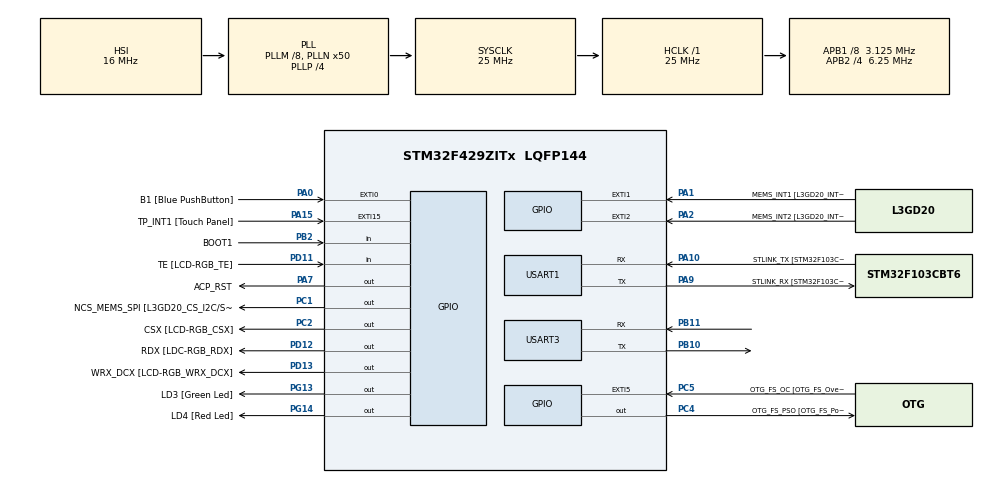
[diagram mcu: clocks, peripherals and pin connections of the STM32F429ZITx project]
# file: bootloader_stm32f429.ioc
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Mcu.Family=STM32F4
Mcu.Name=STM32F429ZITx
Mcu.Package=LQFP144
NVIC.PriorityGroup=NVIC_PRIORITYGROUP_0
PA0/WKUP.GPIO_Label=B1 [Blue PushButton]
PA0/WKUP.GPIO_ModeDefaultEXTI=GPIO_MODE_EVT_RISING
PA0/WKUP.GPIO_PuPd=GPIO_NOPULL
PA0/WKUP.Signal=GPXTI0
PA1.GPIO_Label=MEMS_INT1 [L3GD20_INT1]
PA1.GPIO_ModeDefaultEXTI=GPIO_MODE_EVT_RISING
PA1.GPIO_PuPd=GPIO_NOPULL
PA1.Signal=GPXTI1
PA10.GPIO_Label=STLINK_TX [STM32F103CBT6_PA2]
PA10.Mode=Asynchronous
PA10.Signal=USART1_RX
PA11.GPIO_Label=R4
PA11.GPIO_Mode=GPIO_MODE_AF_PP
PA11.GPIO_PuPd=GPIO_NOPULL
PA11.GPIO_Speed=GPIO_SPEED_FREQ_LOW
PA11.Signal=LTDC_R4
PA12.GPIO_Label=R5
PA12.GPIO_Mode=GPIO_MODE_AF_PP
PA12.GPIO_PuPd=GPIO_NOPULL
PA12.GPIO_Speed=GPIO_SPEED_FREQ_LOW
PA12.Signal=LTDC_R5
PA13.GPIO_Label=SWDIO
PA13.Signal=SYS_JTMS-SWDIO
PA14.GPIO_Label=SWCLK
PA14.Signal=SYS_JTCK-SWCLK
PA15.GPIO_Label=TP_INT1 [Touch Panel]
PA15.GPIO_ModeDefaultEXTI=GPIO_MODE_EVT_RISING
PA15.GPIO_PuPd=GPIO_NOPULL
PA15.Signal=GPXTI15
PA2.GPIO_Label=MEMS_INT2 [L3GD20_INT2]
PA2.GPIO_ModeDefaultEXTI=GPIO_MODE_EVT_RISING
PA2.GPIO_PuPd=GPIO_NOPULL
PA2.Signal=GPXTI2
PA3.GPIO_Label=B5
PA3.GPIO_Mode=GPIO_MODE_AF_PP
PA3.GPIO_PuPd=GPIO_NOPULL
PA3.GPIO_Speed=GPIO_SPEED_FREQ_LOW
PA3.Signal=LTDC_B5
PA4.GPIO_Label=VSYNC
PA4.GPIO_Mode=GPIO_MODE_AF_PP
PA4.GPIO_PuPd=GPIO_NOPULL
PA4.GPIO_Speed=GPIO_SPEED_FREQ_LOW
PA4.Signal=LTDC_VSYNC
PA6.GPIO_Label=G2
PA6.GPIO_Mode=GPIO_MODE_AF_PP
PA6.GPIO_PuPd=GPIO_NOPULL
PA6.GPIO_Speed=GPIO_SPEED_FREQ_LOW
PA6.Signal=LTDC_G2
PA7.GPIO_Label=ACP_RST
PA7.GPIO_Mode=GPIO_MODE_OUTPUT_PP
PA7.GPIO_PuPd=GPIO_NOPULL
PA7.GPIO_Speed=GPIO_SPEED_FREQ_LOW
PA7.Signal=GPIO_Output
PA8.GPIO_Label=I2C3_SCL [ACP/RF_SCL]
PA8.GPIO_Mode=GPIO_MODE_AF_OD
PA8.GPIO_PuPd=GPIO_NOPULL
PA8.GPIO_Speed=GPIO_SPEED_FREQ_LOW
PA8.Signal=I2C3_SCL
PA9.GPIO_Label=STLINK_RX [STM32F103CBT6_PA3]
PA9.Mode=Asynchronous
PA9.Signal=USART1_TX
PB0.GPIO_Label=R3
PB0.GPIO_Mode=GPIO_MODE_AF_PP
PB0.GPIO_PuPd=GPIO_NOPULL
PB0.GPIO_Speed=GPIO_SPEED_FREQ_LOW
PB0.Signal=LTDC_R3
PB1.GPIO_Label=R6
PB1.GPIO_Mode=GPIO_MODE_AF_PP
PB1.GPIO_PuPd=GPIO_NOPULL
PB1.GPIO_Speed=GPIO_SPEED_FREQ_LOW
PB1.Signal=LTDC_R6
PB10.Mode=Asynchronous
PB10.Signal=USART3_TX
PB11.Mode=Asynchronous
PB11.Signal=USART3_RX
PB12.GPIO_Label=OTG_HS_ID
PB12.GPIO_Mode=GPIO_MODE_AF_PP
PB12.GPIO_PuPd=GPIO_NOPULL
PB12.GPIO_Speed=GPIO_SPEED_FREQ_LOW
PB12.Signal=USB_OTG_HS_ID
PB13.GPIO_Label=VBUS_HS
PB13.GPIO_Mode=GPIO_MODE_INPUT
PB13.GPIO_PuPd=GPIO_NOPULL
PB13.Signal=USB_OTG_HS_VBUS
PB14.GPIO_Label=OTG_HS_DM
PB14.GPIO_Mode=GPIO_MODE_AF_PP
PB14.GPIO_PuPd=GPIO_NOPULL
PB14.GPIO_Speed=GPIO_SPEED_FREQ_LOW
PB14.Signal=USB_OTG_HS_DM
PB15.GPIO_Label=OTG_HS_DP
PB15.GPIO_Mode=GPIO_MODE_AF_PP
PB15.GPIO_PuPd=GPIO_NOPULL
PB15.GPIO_Speed=GPIO_SPEED_FREQ_LOW
PB15.Signal=USB_OTG_HS_DP
PB2/BOOT1.GPIO_Label=BOOT1
PB2/BOOT1.GPIO_Mode=GPIO_MODE_INPUT
PB2/BOOT1.GPIO_PuPd=GPIO_NOPULL
PB2/BOOT1.Signal=GPIO_Input
PB5.GPIO_Label=SDCKE1
PB5.GPIO_Mode=GPIO_MODE_AF_PP
PB5.GPIO_PuPd=GPIO_NOPULL
PB5.GPIO_Speed=GPIO_SPEED_FREQ_VERY_HIGH
PB5.Signal=FMC_SDCKE1
PB6.GPIO_Label=SDNE1 [SDRAM_CS]
PB6.GPIO_Mode=GPIO_MODE_AF_PP
PB6.GPIO_PuPd=GPIO_NOPULL
PB6.GPIO_Speed=GPIO_SPEED_FREQ_VERY_HIGH
PB6.Signal=FMC_SDNE1
PB8.GPIO_Label=B6
PB8.GPIO_Mode=GPIO_MODE_AF_PP
PB8.GPIO_PuPd=GPIO_NOPULL
PB8.GPIO_Speed=GPIO_SPEED_FREQ_LOW
PB8.Signal=LTDC_B6
PB9.GPIO_Label=B7
PB9.GPIO_Mode=GPIO_MODE_AF_PP
PB9.GPIO_PuPd=GPIO_NOPULL
PB9.GPIO_Speed=GPIO_SPEED_FREQ_LOW
PB9.Signal=LTDC_B7
PC0.GPIO_Label=SDNWE
PC0.GPIO_Mode=GPIO_MODE_AF_PP
PC0.GPIO_PuPd=GPIO_NOPULL
PC0.GPIO_Speed=GPIO_SPEED_FREQ_VERY_HIGH
PC0.Signal=FMC_SDNWE
PC1.GPIO_Label=NCS_MEMS_SPI [L3GD20_CS_I2C/SPI]
PC1.GPIO_Mode=GPIO_MODE_OUTPUT_PP
PC1.GPIO_PuPd=GPIO_NOPULL
PC1.GPIO_Speed=GPIO_SPEED_FREQ_LOW
PC1.Signal=GPIO_Output
PC14/OSC32_IN.GPIO_Label=PC14-OSC32_IN
PC14/OSC32_IN.Signal=RCC_OSC32_IN
PC15/OSC32_OUT.GPIO_Label=PC15-OSC32_OUT
PC15/OSC32_OUT.Signal=RCC_OSC32_OUT
PC2.GPIO_Label=CSX [LCD-RGB_CSX]
PC2.GPIO_Mode=GPIO_MODE_OUTPUT_PP
PC2.GPIO_PuPd=GPIO_NOPULL
PC2.GPIO_Speed=GPIO_SPEED_FREQ_LOW
PC2.Signal=GPIO_Output
PC4.GPIO_Label=OTG_FS_PSO [OTG_FS_PowerSwitchOn]
PC4.GPIO_Mode=GPIO_MODE_OUTPUT_PP
PC4.GPIO_PuPd=GPIO_NOPULL
PC4.GPIO_Speed=GPIO_SPEED_FREQ_LOW
PC4.Signal=GPIO_Output
PC5.GPIO_Label=OTG_FS_OC [OTG_FS_OverCurrent]
PC5.GPIO_ModeDefaultEXTI=GPIO_MODE_EVT_RISING
PC5.Signal=GPXTI5
PC6.GPIO_Label=HSYNC
PC6.GPIO_Mode=GPIO_MODE_AF_PP
PC6.GPIO_PuPd=GPIO_NOPULL
PC6.GPIO_Speed=GPIO_SPEED_FREQ_LOW
PC6.Signal=LTDC_HSYNC
PC7.GPIO_Label=G6
PC7.GPIO_Mode=GPIO_MODE_AF_PP
PC7.GPIO_PuPd=GPIO_NOPULL
PC7.GPIO_Speed=GPIO_SPEED_FREQ_LOW
PC7.Signal=LTDC_G6
PC9.GPIO_Label=I2C3_SDA [ACP/RF_SDA]
PC9.GPIO_Mode=GPIO_MODE_AF_OD
PC9.GPIO_PuPd=GPIO_NOPULL
PC9.GPIO_Speed=GPIO_SPEED_FREQ_LOW
PC9.Signal=I2C3_SDA
PD0.GPIO_Label=D2
PD0.GPIO_Mode=GPIO_MODE_AF_PP
PD0.GPIO_PuPd=GPIO_NOPULL
PD0.GPIO_Speed=GPIO_SPEED_FREQ_VERY_HIGH
PD0.Signal=FMC_D2_DA2
PD1.GPIO_Label=D3
PD1.GPIO_Mode=GPIO_MODE_AF_PP
PD1.GPIO_PuPd=GPIO_NOPULL
PD1.GPIO_Speed=GPIO_SPEED_FREQ_VERY_HIGH
PD1.Signal=FMC_D3_DA3
PD10.GPIO_Label=D15
PD10.GPIO_Mode=GPIO_MODE_AF_PP
PD10.GPIO_PuPd=GPIO_NOPULL
PD10.GPIO_Speed=GPIO_SPEED_FREQ_VERY_HIGH
PD10.Signal=FMC_D15_DA15
PD11.GPIO_Label=TE [LCD-RGB_TE]
PD11.GPIO_Mode=GPIO_MODE_INPUT
PD11.GPIO_PuPd=GPIO_NOPULL
PD11.Signal=GPIO_Input
PD12.GPIO_Label=RDX [LDC-RGB_RDX]
PD12.GPIO_Mode=GPIO_MODE_OUTPUT_PP
PD12.GPIO_PuPd=GPIO_NOPULL
PD12.GPIO_Speed=GPIO_SPEED_FREQ_LOW
PD12.Signal=GPIO_Output
PD13.GPIO_Label=WRX_DCX [LCD-RGB_WRX_DCX]
PD13.GPIO_Mode=GPIO_MODE_OUTPUT_PP
PD13.GPIO_PuPd=GPIO_NOPULL
PD13.GPIO_Speed=GPIO_SPEED_FREQ_LOW
PD13.Signal=GPIO_Output
PD14.GPIO_Label=D0
PD14.GPIO_Mode=GPIO_MODE_AF_PP
PD14.GPIO_PuPd=GPIO_NOPULL
PD14.GPIO_Speed=GPIO_SPEED_FREQ_VERY_HIGH
PD14.Signal=FMC_D0_DA0
PD15.GPIO_Label=D1
PD15.GPIO_Mode=GPIO_MODE_AF_PP
PD15.GPIO_PuPd=GPIO_NOPULL
PD15.GPIO_Speed=GPIO_SPEED_FREQ_VERY_HIGH
PD15.Signal=FMC_D1_DA1
PD3.GPIO_Label=G7
PD3.GPIO_Mode=GPIO_MODE_AF_PP
PD3.GPIO_PuPd=GPIO_NOPULL
PD3.GPIO_Speed=GPIO_SPEED_FREQ_LOW
PD3.Signal=LTDC_G7
PD6.GPIO_Label=B2
PD6.GPIO_Mode=GPIO_MODE_AF_PP
PD6.GPIO_PuPd=GPIO_NOPULL
PD6.GPIO_Speed=GPIO_SPEED_FREQ_LOW
PD6.Signal=LTDC_B2
PD8.GPIO_Label=D13
PD8.GPIO_Mode=GPIO_MODE_AF_PP
PD8.GPIO_PuPd=GPIO_NOPULL
PD8.GPIO_Speed=GPIO_SPEED_FREQ_VERY_HIGH
PD8.Signal=FMC_D13_DA13
PD9.GPIO_Label=D14
PD9.GPIO_Mode=GPIO_MODE_AF_PP
PD9.GPIO_PuPd=GPIO_NOPULL
PD9.GPIO_Speed=GPIO_SPEED_FREQ_VERY_HIGH
PD9.Signal=FMC_D14_DA14
PE0.GPIO_Label=NBL0 [SDRAM_LDQM]
PE0.GPIO_Mode=GPIO_MODE_AF_PP
PE0.GPIO_PuPd=GPIO_NOPULL
PE0.GPIO_Speed=GPIO_SPEED_FREQ_VERY_HIGH
PE0.Signal=FMC_NBL0
PE1.GPIO_Label=NBL1 [SDRAM_UDQM]
PE1.GPIO_Mode=GPIO_MODE_AF_PP
PE1.GPIO_PuPd=GPIO_NOPULL
PE1.GPIO_Speed=GPIO_SPEED_FREQ_VERY_HIGH
PE1.Signal=FMC_NBL1
PE10.GPIO_Label=D7
PE10.GPIO_Mode=GPIO_MODE_AF_PP
PE10.GPIO_PuPd=GPIO_NOPULL
PE10.GPIO_Speed=GPIO_SPEED_FREQ_VERY_HIGH
PE10.Signal=FMC_D7_DA7
PE11.GPIO_Label=D8
PE11.GPIO_Mode=GPIO_MODE_AF_PP
PE11.GPIO_PuPd=GPIO_NOPULL
PE11.GPIO_Speed=GPIO_SPEED_FREQ_VERY_HIGH
PE11.Signal=FMC_D8_DA8
PE12.GPIO_Label=D9
PE12.GPIO_Mode=GPIO_MODE_AF_PP
PE12.GPIO_PuPd=GPIO_NOPULL
PE12.GPIO_Speed=GPIO_SPEED_FREQ_VERY_HIGH
PE12.Signal=FMC_D9_DA9
PE13.GPIO_Label=D10
PE13.GPIO_Mode=GPIO_MODE_AF_PP
PE13.GPIO_PuPd=GPIO_NOPULL
PE13.GPIO_Speed=GPIO_SPEED_FREQ_VERY_HIGH
PE13.Signal=FMC_D10_DA10
PE14.GPIO_Label=D11
PE14.GPIO_Mode=GPIO_MODE_AF_PP
PE14.GPIO_PuPd=GPIO_NOPULL
PE14.GPIO_Speed=GPIO_SPEED_FREQ_VERY_HIGH
PE14.Signal=FMC_D11_DA11
PE15.GPIO_Label=D12
PE15.GPIO_Mode=GPIO_MODE_AF_PP
PE15.GPIO_PuPd=GPIO_NOPULL
PE15.GPIO_Speed=GPIO_SPEED_FREQ_VERY_HIGH
PE15.Signal=FMC_D12_DA12
PE7.GPIO_Label=D4
PE7.GPIO_Mode=GPIO_MODE_AF_PP
PE7.GPIO_PuPd=GPIO_NOPULL
PE7.GPIO_Speed=GPIO_SPEED_FREQ_VERY_HIGH
PE7.Signal=FMC_D4_DA4
PE8.GPIO_Label=D5
PE8.GPIO_Mode=GPIO_MODE_AF_PP
PE8.GPIO_PuPd=GPIO_NOPULL
PE8.GPIO_Speed=GPIO_SPEED_FREQ_VERY_HIGH
PE8.Signal=FMC_D5_DA5
PE9.GPIO_Label=D6
PE9.GPIO_Mode=GPIO_MODE_AF_PP
PE9.GPIO_PuPd=GPIO_NOPULL
PE9.GPIO_Speed=GPIO_SPEED_FREQ_VERY_HIGH
PE9.Signal=FMC_D6_DA6
PF0.GPIO_Label=A0
PF0.GPIO_Mode=GPIO_MODE_AF_PP
PF0.GPIO_PuPd=GPIO_NOPULL
PF0.GPIO_Speed=GPIO_SPEED_FREQ_VERY_HIGH
PF0.Signal=FMC_A0
PF1.GPIO_Label=A1
PF1.GPIO_Mode=GPIO_MODE_AF_PP
PF1.GPIO_PuPd=GPIO_NOPULL
PF1.GPIO_Speed=GPIO_SPEED_FREQ_VERY_HIGH
PF1.Signal=FMC_A1
PF10.GPIO_Label=ENABLE [LCD-RGB_ENABLE]
PF10.GPIO_Mode=GPIO_MODE_AF_PP
PF10.GPIO_PuPd=GPIO_NOPULL
PF10.GPIO_Speed=GPIO_SPEED_FREQ_LOW
PF10.Signal=LTDC_DE
PF11.GPIO_Label=SDNRAS
PF11.GPIO_Mode=GPIO_MODE_AF_PP
PF11.GPIO_PuPd=GPIO_NOPULL
PF11.GPIO_Speed=GPIO_SPEED_FREQ_VERY_HIGH
PF11.Signal=FMC_SDNRAS
PF12.GPIO_Label=A6
PF12.GPIO_Mode=GPIO_MODE_AF_PP
PF12.GPIO_PuPd=GPIO_NOPULL
PF12.GPIO_Speed=GPIO_SPEED_FREQ_VERY_HIGH
PF12.Signal=FMC_A6
PF13.GPIO_Label=A7
PF13.GPIO_Mode=GPIO_MODE_AF_PP
PF13.GPIO_PuPd=GPIO_NOPULL
PF13.GPIO_Speed=GPIO_SPEED_FREQ_VERY_HIGH
PF13.Signal=FMC_A7
PF14.GPIO_Label=A8
PF14.GPIO_Mode=GPIO_MODE_AF_PP
PF14.GPIO_PuPd=GPIO_NOPULL
PF14.GPIO_Speed=GPIO_SPEED_FREQ_VERY_HIGH
PF14.Signal=FMC_A8
PF15.GPIO_Label=A9
PF15.GPIO_Mode=GPIO_MODE_AF_PP
PF15.GPIO_PuPd=GPIO_NOPULL
PF15.GPIO_Speed=GPIO_SPEED_FREQ_VERY_HIGH
PF15.Signal=FMC_A9
PF2.GPIO_Label=A2
PF2.GPIO_Mode=GPIO_MODE_AF_PP
PF2.GPIO_PuPd=GPIO_NOPULL
PF2.GPIO_Speed=GPIO_SPEED_FREQ_VERY_HIGH
PF2.Signal=FMC_A2
PF3.GPIO_Label=A3
PF3.GPIO_Mode=GPIO_MODE_AF_PP
PF3.GPIO_PuPd=GPIO_NOPULL
PF3.GPIO_Speed=GPIO_SPEED_FREQ_VERY_HIGH
PF3.Signal=FMC_A3
PF4.GPIO_Label=A4
PF4.GPIO_Mode=GPIO_MODE_AF_PP
PF4.GPIO_PuPd=GPIO_NOPULL
PF4.GPIO_Speed=GPIO_SPEED_FREQ_VERY_HIGH
PF4.Signal=FMC_A4
PF5.GPIO_Label=A5
PF5.GPIO_Mode=GPIO_MODE_AF_PP
PF5.GPIO_PuPd=GPIO_NOPULL
PF5.GPIO_Speed=GPIO_SPEED_FREQ_VERY_HIGH
PF5.Signal=FMC_A5
PF7.GPIO_Label=SPI5_SCK [L3GD20_SCL/SPC]
PF7.GPIO_Mode=GPIO_MODE_AF_PP
PF7.GPIO_PuPd=GPIO_NOPULL
PF7.GPIO_Speed=GPIO_SPEED_FREQ_LOW
PF7.Signal=SPI5_SCK
PF8.GPIO_Label=SPI5_MISO [L3GD20_SDO]
PF8.GPIO_Mode=GPIO_MODE_AF_PP
PF8.GPIO_PuPd=GPIO_NOPULL
PF8.GPIO_Speed=GPIO_SPEED_FREQ_LOW
PF8.Signal=SPI5_MISO
PF9.GPIO_Label=SPI5_MOSI [L3GD20_SDA/SDI/SDO]
PF9.GPIO_Mode=GPIO_MODE_AF_PP
PF9.GPIO_PuPd=GPIO_NOPULL
PF9.GPIO_Speed=GPIO_SPEED_FREQ_LOW
PF9.Signal=SPI5_MOSI
PG0.GPIO_Label=A10
PG0.GPIO_Mode=GPIO_MODE_AF_PP
PG0.GPIO_PuPd=GPIO_NOPULL
PG0.GPIO_Speed=GPIO_SPEED_FREQ_VERY_HIGH
PG0.Signal=FMC_A10
PG1.GPIO_Label=A11
PG1.GPIO_Mode=GPIO_MODE_AF_PP
PG1.GPIO_PuPd=GPIO_NOPULL
PG1.GPIO_Speed=GPIO_SPEED_FREQ_VERY_HIGH
PG1.Signal=FMC_A11
PG10.GPIO_Label=G3
PG10.GPIO_Mode=GPIO_MODE_AF_PP
PG10.GPIO_PuPd=GPIO_NOPULL
PG10.GPIO_Speed=GPIO_SPEED_FREQ_LOW
PG10.Signal=LTDC_G3
PG11.GPIO_Label=B3
PG11.GPIO_Mode=GPIO_MODE_AF_PP
PG11.GPIO_PuPd=GPIO_NOPULL
PG11.GPIO_Speed=GPIO_SPEED_FREQ_LOW
PG11.Signal=LTDC_B3
PG12.GPIO_Label=B4
PG12.GPIO_Mode=GPIO_MODE_AF_PP
PG12.GPIO_PuPd=GPIO_NOPULL
PG12.GPIO_Speed=GPIO_SPEED_FREQ_LOW
PG12.Signal=LTDC_B4
PG13.GPIO_Label=LD3 [Green Led]
PG13.GPIO_Mode=GPIO_MODE_OUTPUT_PP
PG13.GPIO_PuPd=GPIO_NOPULL
PG13.GPIO_Speed=GPIO_SPEED_FREQ_LOW
PG13.Signal=GPIO_Output
PG14.GPIO_Label=LD4 [Red Led]
PG14.GPIO_Mode=GPIO_MODE_OUTPUT_PP
PG14.GPIO_PuPd=GPIO_NOPULL
PG14.GPIO_Speed=GPIO_SPEED_FREQ_LOW
PG14.Signal=GPIO_Output
PG15.GPIO_Label=SDNCAS
PG15.GPIO_Mode=GPIO_MODE_AF_PP
PG15.GPIO_PuPd=GPIO_NOPULL
PG15.GPIO_Speed=GPIO_SPEED_FREQ_VERY_HIGH
PG15.Signal=FMC_SDNCAS
PG4.GPIO_Label=BA0
PG4.GPIO_Mode=GPIO_MODE_AF_PP
PG4.GPIO_PuPd=GPIO_NOPULL
PG4.GPIO_Speed=GPIO_SPEED_FREQ_VERY_HIGH
PG4.Signal=FMC_A14_BA0
PG5.GPIO_Label=BA1
PG5.GPIO_Mode=GPIO_MODE_AF_PP
PG5.GPIO_PuPd=GPIO_NOPULL
PG5.GPIO_Speed=GPIO_SPEED_FREQ_VERY_HIGH
PG5.Signal=FMC_A15_BA1
PG6.GPIO_Label=R7
PG6.GPIO_Mode=GPIO_MODE_AF_PP
PG6.GPIO_PuPd=GPIO_NOPULL
PG6.GPIO_Speed=GPIO_SPEED_FREQ_LOW
PG6.Signal=LTDC_R7
PG7.GPIO_Label=DOTCLK [LCT-RGB_DOTCLK]
PG7.GPIO_Mode=GPIO_MODE_AF_PP
PG7.GPIO_PuPd=GPIO_NOPULL
PG7.GPIO_Speed=GPIO_SPEED_FREQ_LOW
PG7.Signal=LTDC_CLK
PG8.GPIO_Label=SDCLK
PG8.GPIO_Mode=GPIO_MODE_AF_PP
PG8.GPIO_PuPd=GPIO_NOPULL
PG8.GPIO_Speed=GPIO_SPEED_FREQ_VERY_HIGH
PG8.Signal=FMC_SDCLK
PH0/OSC_IN.GPIO_Label=PH0-OSC_IN
PH0/OSC_IN.Signal=RCC_OSC_IN
PH1/OSC_OUT.GPIO_Label=PH1-OSC_OUT
PH1/OSC_OUT.Signal=RCC_OSC_OUT
ProjectManager.HeapSize=0x200
ProjectManager.StackSize=0x400
ProjectManager.TargetToolchain=MDK-ARM V5
RCC.48MHZClocksFreq_Value=14285714.285714285
RCC.AHBFreq_Value=25000000
RCC.APB1CLKDivider=RCC_HCLK_DIV8
RCC.APB1Freq_Value=3125000
RCC.APB1TimFreq_Value=6250000
RCC.APB2CLKDivider=RCC_HCLK_DIV4
RCC.APB2Freq_Value=6250000
RCC.APB2TimFreq_Value=12500000
RCC.CortexFreq_Value=25000000
RCC.HCLKFreq_Value=25000000
RCC.HSE_VALUE=8000000
RCC.HSI_VALUE=16000000
RCC.LSE_VALUE=32768
RCC.PLLM=8
RCC.PLLN=50
RCC.PLLP=RCC_PLLP_DIV4
RCC.PLLQ=7
RCC.SYSCLKFreq_VALUE=25000000
RCC.SYSCLKSource=RCC_SYSCLKSOURCE_PLLCLK
RCC.VCOOutputFreq_Value=100000000
SH.FMC_A0.0=FMC_A0
SH.FMC_A1.0=FMC_A1
SH.FMC_A10.0=FMC_A10
SH.FMC_A11.0=FMC_A11
SH.FMC_A14_BA0.0=FMC_BA0
SH.FMC_A15_BA1.0=FMC_BA1
SH.FMC_A2.0=FMC_A2
SH.FMC_A3.0=FMC_A3
SH.FMC_A4.0=FMC_A4
SH.FMC_A5.0=FMC_A5
SH.FMC_A6.0=FMC_A6
SH.FMC_A7.0=FMC_A7
SH.FMC_A8.0=FMC_A8
SH.FMC_A9.0=FMC_A9
SH.FMC_D0_DA0.0=FMC_D0
SH.FMC_D10_DA10.0=FMC_D10
SH.FMC_D11_DA11.0=FMC_D11
SH.FMC_D12_DA12.0=FMC_D12
SH.FMC_D13_DA13.0=FMC_D13
SH.FMC_D14_DA14.0=FMC_D14
SH.FMC_D15_DA15.0=FMC_D15
SH.FMC_D1_DA1.0=FMC_D1
SH.FMC_D2_DA2.0=FMC_D2
SH.FMC_D3_DA3.0=FMC_D3
SH.FMC_D4_DA4.0=FMC_D4
SH.FMC_D5_DA5.0=FMC_D5
SH.FMC_D6_DA6.0=FMC_D6
SH.FMC_D7_DA7.0=FMC_D7
SH.FMC_D8_DA8.0=FMC_D8
SH.FMC_D9_DA9.0=FMC_D9
SH.FMC_NBL0.0=FMC_NBL0
SH.FMC_NBL1.0=FMC_NBL1
SH.FMC_SDCLK.0=FMC_SDCLK
SH.FMC_SDNCAS.0=FMC_SDNCAS
SH.FMC_SDNRAS.0=FMC_SDNRAS
SH.FMC_SDNWE.0=FMC_SDNWE
USART1.VirtualMode=VM_ASYNC
USART3.VirtualMode=VM_ASYNC
VP_CRC_VS_CRC.Mode=CRC_Activate
board=STM32F429I-DISC1

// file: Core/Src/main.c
/* USER CODE BEGIN Header */
/**
  ******************************************************************************
  * @file           : main.c
  * @brief          : Main program body
  ******************************************************************************
  * @attention
  *
  * <h2><center>&copy; Copyright (c) 2021 STMicroelectronics.
  * All rights reserved.</center></h2>
  *
  * This software component is licensed by ST under BSD 3-Clause license,
  * the "License"; You may not use this file except in compliance with the
  * License. You may obtain a copy of the License at:
  *                        opensource.org/licenses/BSD-3-Clause
  *
  ******************************************************************************
  */
/* USER CODE END Header */

#include <stdarg.h>
#include <string.h>

#include "main.h"

/* USER CODE BEGIN PM */

/* enable this line to get debug messages over debug Uart */
#define BL_DEBUG_MSG_EN
/* USER CODE END PM */

CRC_HandleTypeDef hcrc;

UART_HandleTypeDef huart1;
UART_HandleTypeDef huart3;

uint8_t supported_commands[] = {
																BL_GET_VER,
																BL_GET_HELP,
																BL_GET_CID,
																BL_GET_RDP_STATUS,
																BL_GO_TO_ADDR,
																BL_FLASH_ERASE,
																BL_MEM_WRITE,
																BL_EN_R_W_PROTECT,
																BL_MEM_READ,
																BL_READ_SECTOR_STATUS,
																BL_OTP_READ,
																BL_DIS_R_W_PROTECT
															};

#define C_UART &huart1
#define D_UART &huart3
#define FLASH_SECTOR2_BASE_ADDRESS 0x08008000U

#define HAL_FLASH_MODULE_ENABLED

void SystemClock_Config(void);
static void MX_GPIO_Init(void);
static void MX_CRC_Init(void);
static void MX_USART1_UART_Init(void);
static void MX_USART3_UART_Init(void);
/* USER CODE BEGIN PFP */

static void printmsg (char *format, ...);
/* USER CODE END PFP */

/* USER CODE BEGIN 0 */
char somedata1[] = "Hellow from Bootloader UART1\r\n";
char somedata2[] = "Hellow from Bootloader UART3\r\n";

#define BL_RX_LEN 200
uint8_t bl_rx_buffer [BL_RX_LEN];
/* USER CODE END 0 */

int main(void)
{

  /* MCU Configuration--------------------------------------------------------*/

  /* Reset of all peripherals, Initializes the Flash interface and the Systick. */
  HAL_Init();

  /* Configure the system clock */
  SystemClock_Config();

  /* Initialize all configured peripherals */
  MX_GPIO_Init();
  MX_CRC_Init();
  MX_USART1_UART_Init();
  MX_USART3_UART_Init();

  /* Infinite loop */
  /* USER CODE BEGIN WHILE */
  //
	#if 0
	while (1)
  {
    /* USER CODE END WHILE */

		HAL_UART_Transmit ( &huart1, (uint8_t*)somedata1 , sizeof(somedata1), HAL_MAX_DELAY );
	  HAL_UART_Transmit ( &huart3, (uint8_t*)somedata2 , sizeof(somedata2), HAL_MAX_DELAY );
		uint32_t current_tick = HAL_GetTick();
		printmsg("current_tick = %d \r\n",current_tick);
		while( HAL_GetTick() <= current_tick+500 );
		#endif

		if( HAL_GPIO_ReadPin( B1_GPIO_Port, B1_Pin ) == GPIO_PIN_SET )
		{
			printmsg( "BL_Debug_MSG: Button is pressed .. going to BL mode\r\n");
			/*******UART3 Test**************/
	/*		HAL_UART_Transmit ( &huart1, (uint8_t*)somedata1 , sizeof(somedata1), HAL_MAX_DELAY );
	    HAL_UART_Transmit ( &huart3, (uint8_t*)somedata2 , sizeof(somedata2), HAL_MAX_DELAY );
		  uint32_t current_tick = HAL_GetTick();
		  printmsg("current_tick = %d \r\n",current_tick);
		  while( HAL_GetTick() <= current_tick+500 );*/
			/*******UART3 Test end **************/
			bootloader_uart_read_data();
		}

		else
		{
			printmsg( "BL_Debug_MSG: Button is not pressed .. going to user app\r\n");
			/*******UART3 Test**************/
			HAL_UART_Transmit ( &huart1, (uint8_t*)somedata1 , sizeof(somedata1), HAL_MAX_DELAY );
	    HAL_UART_Transmit ( &huart3, (uint8_t*)somedata2 , sizeof(somedata2), HAL_MAX_DELAY );
		  uint32_t current_tick = HAL_GetTick();
		  printmsg("current_tick = %d \r\n",current_tick);
		  while( HAL_GetTick() <= current_tick+500 );
			/*******UART3 Test end **************/
			bootloader_jump_to_user_app();
		}
}

void SystemClock_Config(void)
{
  RCC_OscInitTypeDef RCC_OscInitStruct = {0};
  RCC_ClkInitTypeDef RCC_ClkInitStruct = {0};

  /** Configure the main internal regulator output voltage
  */
  __HAL_RCC_PWR_CLK_ENABLE();
  __HAL_PWR_VOLTAGESCALING_CONFIG(PWR_REGULATOR_VOLTAGE_SCALE3);
  /** Initializes the RCC Oscillators according to the specified parameters
  * in the RCC_OscInitTypeDef structure.
  */
  RCC_OscInitStruct.OscillatorType = RCC_OSCILLATORTYPE_HSI;
  RCC_OscInitStruct.HSIState = RCC_HSI_ON;
  RCC_OscInitStruct.HSICalibrationValue = RCC_HSICALIBRATION_DEFAULT;
  RCC_OscInitStruct.PLL.PLLState = RCC_PLL_ON;
  RCC_OscInitStruct.PLL.PLLSource = RCC_PLLSOURCE_HSI;
  RCC_OscInitStruct.PLL.PLLM = 8;
  RCC_OscInitStruct.PLL.PLLN = 50;
  RCC_OscInitStruct.PLL.PLLP = RCC_PLLP_DIV4;
  RCC_OscInitStruct.PLL.PLLQ = 7;
  if (HAL_RCC_OscConfig(&RCC_OscInitStruct) != HAL_OK)
  {
    Error_Handler();
  }
  /** Initializes the CPU, AHB and APB buses clocks
  */
  RCC_ClkInitStruct.ClockType = RCC_CLOCKTYPE_HCLK|RCC_CLOCKTYPE_SYSCLK
                              |RCC_CLOCKTYPE_PCLK1|RCC_CLOCKTYPE_PCLK2;
  RCC_ClkInitStruct.SYSCLKSource = RCC_SYSCLKSOURCE_PLLCLK;
  RCC_ClkInitStruct.AHBCLKDivider = RCC_SYSCLK_DIV1;
  RCC_ClkInitStruct.APB1CLKDivider = RCC_HCLK_DIV8;
  RCC_ClkInitStruct.APB2CLKDivider = RCC_HCLK_DIV4;

  if (HAL_RCC_ClockConfig(&RCC_ClkInitStruct, FLASH_LATENCY_0) != HAL_OK)
  {
    Error_Handler();
  }
}

static void MX_CRC_Init(void)
{

  hcrc.Instance = CRC;
  if (HAL_CRC_Init(&hcrc) != HAL_OK)
  {
    Error_Handler();
  }

}

static void MX_USART1_UART_Init(void)
{

  huart1.Instance = USART1;
  huart1.Init.BaudRate = 115200;
  huart1.Init.WordLength = UART_WORDLENGTH_8B;
  huart1.Init.StopBits = UART_STOPBITS_1;
  huart1.Init.Parity = UART_PARITY_NONE;
  huart1.Init.Mode = UART_MODE_TX_RX;
  huart1.Init.HwFlowCtl = UART_HWCONTROL_NONE;
  huart1.Init.OverSampling = UART_OVERSAMPLING_16;
  if (HAL_UART_Init(&huart1) != HAL_OK)
  {
    Error_Handler();
  }

}

static void MX_USART3_UART_Init(void)
{

  huart3.Instance = USART3;
  huart3.Init.BaudRate = 115200;
  huart3.Init.WordLength = UART_WORDLENGTH_8B;
  huart3.Init.StopBits = UART_STOPBITS_1;
  huart3.Init.Parity = UART_PARITY_NONE;
  huart3.Init.Mode = UART_MODE_TX_RX;
  huart3.Init.HwFlowCtl = UART_HWCONTROL_NONE;
  huart3.Init.OverSampling = UART_OVERSAMPLING_16;
  if (HAL_UART_Init(&huart3) != HAL_OK)
  {
    Error_Handler();
  }

}

static void MX_GPIO_Init(void)
{
  GPIO_InitTypeDef GPIO_InitStruct = {0};

  /* GPIO Ports Clock Enable */
  __HAL_RCC_GPIOC_CLK_ENABLE();
  __HAL_RCC_GPIOF_CLK_ENABLE();
  __HAL_RCC_GPIOH_CLK_ENABLE();
  __HAL_RCC_GPIOA_CLK_ENABLE();
  __HAL_RCC_GPIOB_CLK_ENABLE();
  __HAL_RCC_GPIOG_CLK_ENABLE();
  __HAL_RCC_GPIOE_CLK_ENABLE();
  __HAL_RCC_GPIOD_CLK_ENABLE();

  /*Configure GPIO pin Output Level */
  HAL_GPIO_WritePin(GPIOC, NCS_MEMS_SPI_Pin|CSX_Pin|OTG_FS_PSO_Pin, GPIO_PIN_RESET);

  /*Configure GPIO pin Output Level */
  HAL_GPIO_WritePin(ACP_RST_GPIO_Port, ACP_RST_Pin, GPIO_PIN_RESET);

  /*Configure GPIO pin Output Level */
  HAL_GPIO_WritePin(GPIOD, RDX_Pin|WRX_DCX_Pin, GPIO_PIN_RESET);

  /*Configure GPIO pin Output Level */
  HAL_GPIO_WritePin(GPIOG, LD3_Pin|LD4_Pin, GPIO_PIN_RESET);

  /*Configure GPIO pins : A0_Pin A1_Pin A2_Pin A3_Pin
                           A4_Pin A5_Pin SDNRAS_Pin A6_Pin
                           A7_Pin A8_Pin A9_Pin */
  GPIO_InitStruct.Pin = A0_Pin|A1_Pin|A2_Pin|A3_Pin
                          |A4_Pin|A5_Pin|SDNRAS_Pin|A6_Pin
                          |A7_Pin|A8_Pin|A9_Pin;
  GPIO_InitStruct.Mode = GPIO_MODE_AF_PP;
  GPIO_InitStruct.Pull = GPIO_NOPULL;
  GPIO_InitStruct.Speed = GPIO_SPEED_FREQ_VERY_HIGH;
  GPIO_InitStruct.Alternate = GPIO_AF12_FMC;
  HAL_GPIO_Init(GPIOF, &GPIO_InitStruct);

  /*Configure GPIO pins : SPI5_SCK_Pin SPI5_MISO_Pin SPI5_MOSI_Pin */
  GPIO_InitStruct.Pin = SPI5_SCK_Pin|SPI5_MISO_Pin|SPI5_MOSI_Pin;
  GPIO_InitStruct.Mode = GPIO_MODE_AF_PP;
  GPIO_InitStruct.Pull = GPIO_NOPULL;
  GPIO_InitStruct.Speed = GPIO_SPEED_FREQ_LOW;
  GPIO_InitStruct.Alternate = GPIO_AF5_SPI5;
  HAL_GPIO_Init(GPIOF, &GPIO_InitStruct);

  /*Configure GPIO pin : ENABLE_Pin */
  GPIO_InitStruct.Pin = ENABLE_Pin;
  GPIO_InitStruct.Mode = GPIO_MODE_AF_PP;
  GPIO_InitStruct.Pull = GPIO_NOPULL;
  GPIO_InitStruct.Speed = GPIO_SPEED_FREQ_LOW;
  GPIO_InitStruct.Alternate = GPIO_AF14_LTDC;
  HAL_GPIO_Init(ENABLE_GPIO_Port, &GPIO_InitStruct);

  /*Configure GPIO pin : SDNWE_Pin */
  GPIO_InitStruct.Pin = SDNWE_Pin;
  GPIO_InitStruct.Mode = GPIO_MODE_AF_PP;
  GPIO_InitStruct.Pull = GPIO_NOPULL;
  GPIO_InitStruct.Speed = GPIO_SPEED_FREQ_VERY_HIGH;
  GPIO_InitStruct.Alternate = GPIO_AF12_FMC;
  HAL_GPIO_Init(SDNWE_GPIO_Port, &GPIO_InitStruct);

  /*Configure GPIO pins : NCS_MEMS_SPI_Pin CSX_Pin OTG_FS_PSO_Pin */
  GPIO_InitStruct.Pin = NCS_MEMS_SPI_Pin|CSX_Pin|OTG_FS_PSO_Pin;
  GPIO_InitStruct.Mode = GPIO_MODE_OUTPUT_PP;
  GPIO_InitStruct.Pull = GPIO_NOPULL;
  GPIO_InitStruct.Speed = GPIO_SPEED_FREQ_LOW;
  HAL_GPIO_Init(GPIOC, &GPIO_InitStruct);

  /*Configure GPIO pins : B1_Pin MEMS_INT1_Pin MEMS_INT2_Pin TP_INT1_Pin */
  GPIO_InitStruct.Pin = B1_Pin|MEMS_INT1_Pin|MEMS_INT2_Pin|TP_INT1_Pin;
  GPIO_InitStruct.Mode = GPIO_MODE_EVT_RISING;
  GPIO_InitStruct.Pull = GPIO_NOPULL;
  HAL_GPIO_Init(GPIOA, &GPIO_InitStruct);

  /*Configure GPIO pins : B5_Pin VSYNC_Pin G2_Pin R4_Pin
                           R5_Pin */
  GPIO_InitStruct.Pin = B5_Pin|VSYNC_Pin|G2_Pin|R4_Pin
                          |R5_Pin;
  GPIO_InitStruct.Mode = GPIO_MODE_AF_PP;
  GPIO_InitStruct.Pull = GPIO_NOPULL;
  GPIO_InitStruct.Speed = GPIO_SPEED_FREQ_LOW;
  GPIO_InitStruct.Alternate = GPIO_AF14_LTDC;
  HAL_GPIO_Init(GPIOA, &GPIO_InitStruct);

  /*Configure GPIO pin : ACP_RST_Pin */
  GPIO_InitStruct.Pin = ACP_RST_Pin;
  GPIO_InitStruct.Mode = GPIO_MODE_OUTPUT_PP;
  GPIO_InitStruct.Pull = GPIO_NOPULL;
  GPIO_InitStruct.Speed = GPIO_SPEED_FREQ_LOW;
  HAL_GPIO_Init(ACP_RST_GPIO_Port, &GPIO_InitStruct);

  /*Configure GPIO pin : OTG_FS_OC_Pin */
  GPIO_InitStruct.Pin = OTG_FS_OC_Pin;
  GPIO_InitStruct.Mode = GPIO_MODE_EVT_RISING;
  GPIO_InitStruct.Pull = GPIO_NOPULL;
  HAL_GPIO_Init(OTG_FS_OC_GPIO_Port, &GPIO_InitStruct);

  /*Configure GPIO pins : R3_Pin R6_Pin */
  GPIO_InitStruct.Pin = R3_Pin|R6_Pin;
  GPIO_InitStruct.Mode = GPIO_MODE_AF_PP;
  GPIO_InitStruct.Pull = GPIO_NOPULL;
  GPIO_InitStruct.Speed = GPIO_SPEED_FREQ_LOW;
  GPIO_InitStruct.Alternate = GPIO_AF9_LTDC;
  HAL_GPIO_Init(GPIOB, &GPIO_InitStruct);

  /*Configure GPIO pin : BOOT1_Pin */
  GPIO_InitStruct.Pin = BOOT1_Pin;
  GPIO_InitStruct.Mode = GPIO_MODE_INPUT;
  GPIO_InitStruct.Pull = GPIO_NOPULL;
  HAL_GPIO_Init(BOOT1_GPIO_Port, &GPIO_InitStruct);

  /*Configure GPIO pins : A10_Pin A11_Pin BA0_Pin BA1_Pin
                           SDCLK_Pin SDNCAS_Pin */
  GPIO_InitStruct.Pin = A10_Pin|A11_Pin|BA0_Pin|BA1_Pin
                          |SDCLK_Pin|SDNCAS_Pin;
  GPIO_InitStruct.Mode = GPIO_MODE_AF_PP;
  GPIO_InitStruct.Pull = GPIO_NOPULL;
  GPIO_InitStruct.Speed = GPIO_SPEED_FREQ_VERY_HIGH;
  GPIO_InitStruct.Alternate = GPIO_AF12_FMC;
  HAL_GPIO_Init(GPIOG, &GPIO_InitStruct);

  /*Configure GPIO pins : D4_Pin D5_Pin D6_Pin D7_Pin
                           D8_Pin D9_Pin D10_Pin D11_Pin
                           D12_Pin NBL0_Pin NBL1_Pin */
  GPIO_InitStruct.Pin = D4_Pin|D5_Pin|D6_Pin|D7_Pin
                          |D8_Pin|D9_Pin|D10_Pin|D11_Pin
                          |D12_Pin|NBL0_Pin|NBL1_Pin;
  GPIO_InitStruct.Mode = GPIO_MODE_AF_PP;
  GPIO_InitStruct.Pull = GPIO_NOPULL;
  GPIO_InitStruct.Speed = GPIO_SPEED_FREQ_VERY_HIGH;
  GPIO_InitStruct.Alternate = GPIO_AF12_FMC;
  HAL_GPIO_Init(GPIOE, &GPIO_InitStruct);

  /*Configure GPIO pins : OTG_HS_ID_Pin OTG_HS_DM_Pin OTG_HS_DP_Pin */
  GPIO_InitStruct.Pin = OTG_HS_ID_Pin|OTG_HS_DM_Pin|OTG_HS_DP_Pin;
  GPIO_InitStruct.Mode = GPIO_MODE_AF_PP;
  GPIO_InitStruct.Pull = GPIO_NOPULL;
  GPIO_InitStruct.Speed = GPIO_SPEED_FREQ_LOW;
  GPIO_InitStruct.Alternate = GPIO_AF12_OTG_HS_FS;
  HAL_GPIO_Init(GPIOB, &GPIO_InitStruct);

  /*Configure GPIO pin : VBUS_HS_Pin */
  GPIO_InitStruct.Pin = VBUS_HS_Pin;
  GPIO_InitStruct.Mode = GPIO_MODE_INPUT;
  GPIO_InitStruct.Pull = GPIO_NOPULL;
  HAL_GPIO_Init(VBUS_HS_GPIO_Port, &GPIO_InitStruct);

  /*Configure GPIO pins : D13_Pin D14_Pin D15_Pin D0_Pin
                           D1_Pin D2_Pin D3_Pin */
  GPIO_InitStruct.Pin = D13_Pin|D14_Pin|D15_Pin|D0_Pin
                          |D1_Pin|D2_Pin|D3_Pin;
  GPIO_InitStruct.Mode = GPIO_MODE_AF_PP;
  GPIO_InitStruct.Pull = GPIO_NOPULL;
  GPIO_InitStruct.Speed = GPIO_SPEED_FREQ_VERY_HIGH;
  GPIO_InitStruct.Alternate = GPIO_AF12_FMC;
  HAL_GPIO_Init(GPIOD, &GPIO_InitStruct);

  /*Configure GPIO pin : TE_Pin */
  GPIO_InitStruct.Pin = TE_Pin;
  GPIO_InitStruct.Mode = GPIO_MODE_INPUT;
  GPIO_InitStruct.Pull = GPIO_NOPULL;
  HAL_GPIO_Init(TE_GPIO_Port, &GPIO_InitStruct);

  /*Configure GPIO pins : RDX_Pin WRX_DCX_Pin */
  GPIO_InitStruct.Pin = RDX_Pin|WRX_DCX_Pin;
  GPIO_InitStruct.Mode = GPIO_MODE_OUTPUT_PP;
  GPIO_InitStruct.Pull = GPIO_NOPULL;
  GPIO_InitStruct.Speed = GPIO_SPEED_FREQ_LOW;
  HAL_GPIO_Init(GPIOD, &GPIO_InitStruct);

  /*Configure GPIO pins : R7_Pin DOTCLK_Pin B3_Pin */
  GPIO_InitStruct.Pin = R7_Pin|DOTCLK_Pin|B3_Pin;
  GPIO_InitStruct.Mode = GPIO_MODE_AF_PP;
  GPIO_InitStruct.Pull = GPIO_NOPULL;
  GPIO_InitStruct.Speed = GPIO_SPEED_FREQ_LOW;
  GPIO_InitStruct.Alternate = GPIO_AF14_LTDC;
  HAL_GPIO_Init(GPIOG, &GPIO_InitStruct);

  /*Configure GPIO pins : HSYNC_Pin G6_Pin */
  GPIO_InitStruct.Pin = HSYNC_Pin|G6_Pin;
  GPIO_InitStruct.Mode = GPIO_MODE_AF_PP;
  GPIO_InitStruct.Pull = GPIO_NOPULL;
  GPIO_InitStruct.Speed = GPIO_SPEED_FREQ_LOW;
  GPIO_InitStruct.Alternate = GPIO_AF14_LTDC;
  HAL_GPIO_Init(GPIOC, &GPIO_InitStruct);

  /*Configure GPIO pin : I2C3_SDA_Pin */
  GPIO_InitStruct.Pin = I2C3_SDA_Pin;
  GPIO_InitStruct.Mode = GPIO_MODE_AF_OD;
  GPIO_InitStruct.Pull = GPIO_NOPULL;
  GPIO_InitStruct.Speed = GPIO_SPEED_FREQ_LOW;
  GPIO_InitStruct.Alternate = GPIO_AF4_I2C3;
  HAL_GPIO_Init(I2C3_SDA_GPIO_Port, &GPIO_InitStruct);

  /*Configure GPIO pin : I2C3_SCL_Pin */
  GPIO_InitStruct.Pin = I2C3_SCL_Pin;
  GPIO_InitStruct.Mode = GPIO_MODE_AF_OD;
  GPIO_InitStruct.Pull = GPIO_NOPULL;
  GPIO_InitStruct.Speed = GPIO_SPEED_FREQ_LOW;
  GPIO_InitStruct.Alternate = GPIO_AF4_I2C3;
  HAL_GPIO_Init(I2C3_SCL_GPIO_Port, &GPIO_InitStruct);

  /*Configure GPIO pins : G7_Pin B2_Pin */
  GPIO_InitStruct.Pin = G7_Pin|B2_Pin;
  GPIO_InitStruct.Mode = GPIO_MODE_AF_PP;
  GPIO_InitStruct.Pull = GPIO_NOPULL;
  GPIO_InitStruct.Speed = GPIO_SPEED_FREQ_LOW;
  GPIO_InitStruct.Alternate = GPIO_AF14_LTDC;
  HAL_GPIO_Init(GPIOD, &GPIO_InitStruct);

  /*Configure GPIO pins : G3_Pin B4_Pin */
  GPIO_InitStruct.Pin = G3_Pin|B4_Pin;
  GPIO_InitStruct.Mode = GPIO_MODE_AF_PP;
  GPIO_InitStruct.Pull = GPIO_NOPULL;
  GPIO_InitStruct.Speed = GPIO_SPEED_FREQ_LOW;
  GPIO_InitStruct.Alternate = GPIO_AF9_LTDC;
  HAL_GPIO_Init(GPIOG, &GPIO_InitStruct);

  /*Configure GPIO pins : LD3_Pin LD4_Pin */
  GPIO_InitStruct.Pin = LD3_Pin|LD4_Pin;
  GPIO_InitStruct.Mode = GPIO_MODE_OUTPUT_PP;
  GPIO_InitStruct.Pull = GPIO_NOPULL;
  GPIO_InitStruct.Speed = GPIO_SPEED_FREQ_LOW;
  HAL_GPIO_Init(GPIOG, &GPIO_InitStruct);

  /*Configure GPIO pins : SDCKE1_Pin SDNE1_Pin */
  GPIO_InitStruct.Pin = SDCKE1_Pin|SDNE1_Pin;
  GPIO_InitStruct.Mode = GPIO_MODE_AF_PP;
  GPIO_InitStruct.Pull = GPIO_NOPULL;
  GPIO_InitStruct.Speed = GPIO_SPEED_FREQ_VERY_HIGH;
  GPIO_InitStruct.Alternate = GPIO_AF12_FMC;
  HAL_GPIO_Init(GPIOB, &GPIO_InitStruct);

  /*Configure GPIO pins : B6_Pin B7_Pin */
  GPIO_InitStruct.Pin = B6_Pin|B7_Pin;
  GPIO_InitStruct.Mode = GPIO_MODE_AF_PP;
  GPIO_InitStruct.Pull = GPIO_NOPULL;
  GPIO_InitStruct.Speed = GPIO_SPEED_FREQ_LOW;
  GPIO_InitStruct.Alternate = GPIO_AF14_LTDC;
  HAL_GPIO_Init(GPIOB, &GPIO_InitStruct);

}

void Error_Handler(void)
{
  __disable_irq();
  while (1)
  {
  }
}

/************************ (C) COPYRIGHT STMicroelectronics *****END OF FILE****/

/***************** Added code for bootloader operations **************************/

void printmsg (char *format, ... )
{
	#ifdef BL_DEBUG_MSG_EN
	char str[80];

	/* Extract the argument list using VA apis */
	va_list args;
	va_start (args, format);
	vsprintf(str, format, args );
	HAL_UART_Transmit ( D_UART, (uint8_t *)str, strlen (str), HAL_MAX_DELAY);
	va_end (args);
	#endif
}

void bootloader_uart_read_data( void )
{
	uint8_t rcv_len = 0;

	while(1)
	{
		memset ( bl_rx_buffer, 0, 200 );
		// here we will read and decode the commands comming from host
		// first read only one byte from the host , which is the "lenght" field of the command
		HAL_UART_Receive ( C_UART, bl_rx_buffer, 1, HAL_MAX_DELAY );
		rcv_len = bl_rx_buffer[0];
		HAL_UART_Receive ( C_UART, &bl_rx_buffer[1], rcv_len, HAL_MAX_DELAY );
		switch ( bl_rx_buffer[1] )
		{
			case BL_GET_VER :
				bootloader_handle_getver_cmd (bl_rx_buffer);
				break;
			case BL_GET_HELP :
				bootloader_handle_gethelp_cmd (bl_rx_buffer);
				break;
			case BL_GET_CID :
				bootloader_handle_getcid_cmd (bl_rx_buffer);
				break;
			case BL_GET_RDP_STATUS :
				bootloader_handle_getrdp_cmd (bl_rx_buffer);
				break;
			case BL_GO_TO_ADDR :
				bootloader_handle_go_cmd (bl_rx_buffer);
				break;
			case BL_FLASH_ERASE :
				bootloader_handle_flash_erase_cmd (bl_rx_buffer);
				break;
			case BL_MEM_WRITE :
				bootloader_handle_mem_write_cmd (bl_rx_buffer);
				break;
			case BL_EN_R_W_PROTECT :
				bootloader_handle_en_rw_protect (bl_rx_buffer);
				break;
			case BL_MEM_READ :
				bootloader_handle_mem_read (bl_rx_buffer);
				break;
			case BL_READ_SECTOR_STATUS :
				bootloader_handle_read_sector_protection_status (bl_rx_buffer);
				break;
			case BL_OTP_READ :
				bootloader_handle_read_otp (bl_rx_buffer);
				break;
      case BL_DIS_R_W_PROTECT:
        bootloader_handle_dis_rw_protect(bl_rx_buffer);
        break;
			default:
				printmsg ( "BL_DEBUG_MSG : Invalid command code received from host \r\n" );
		}
	}
}

/* code to jump to user application
		here we are assuming FLASH_SECTOR2_BASE_ADDRESS
		is where the user application stored
		*/

void bootloader_jump_to_user_app( void )
{
	// function pointer to hold the address of the reset handler of  the user app.
	void (*app_reset_handler) (void);

	printmsg (" BL_DEBUG_MSG : bootloader jump to user app\r\n");

	// configure the MSP by reading th value from the base address of the sector 2
	uint32_t msp_value = * (volatile uint32_t *) FLASH_SECTOR2_BASE_ADDRESS ;
	printmsg ("BL_DEBUG_MSG:MSP Value : %#x\r\n", msp_value );

	// function from CMSIS.
	__set_MSP (msp_value );

	//SCB->VTOR = FLASH_SECTOR1_BASE_ADDRESS;

	/* fetch the reset handler address of the user application
		from the location FLASH_SECTOR2_BASE_ADDRESS+4
	*/

	uint32_t resethandler_address = *(volatile uint32_t *) ( FLASH_SECTOR2_BASE_ADDRESS + 4);
	app_reset_handler = (void*) resethandler_address;
	printmsg ("BL_DEBUG_MSG:app_reset_handler_address : %#x\r\n", app_reset_handler );

	// jump to reset handler of the application
	app_reset_handler();
}

/*********** Implementation of Bootloader command handle function ****************************/

/* helper function to handle BL_GET_VER command */
void bootloader_handle_getver_cmd (uint8_t *bl_rx_buffer)
{
	uint8_t bl_version;
	// Varify the checksum
	printmsg ( "BL_DEBUG_MSG : bootloader_handle_getver_cmd \r\n" );

	//Total lenght of the command packet
	uint32_t command_packet_len = bl_rx_buffer[0]+1 ;

	//extract the CRC32 sent by the host
	uint32_t host_crc = *((uint32_t *) (bl_rx_buffer + command_packet_len - 4 ));

	if ( ! bootloader_verify_crc ( &bl_rx_buffer[0], command_packet_len-4, host_crc) )
	{
		printmsg ( "BL_DEBUG_MSG : checksum success ! !\r\n" );
		// checksum is correct..
		bootloader_send_ack ( bl_rx_buffer[0], 1 );
		bl_version = get_bootloader_version ();
		printmsg ( "BL_DEBUG_MSG : BL_VER : %d %#x\r\n", bl_version, bl_version );
		bootloader_uart_write_data ( &bl_version, 1 );
	}
	else
	{
		printmsg ( "BL_DEBUG_MSG : checksum fail ! !\r\n" );
		// checksum is wrong send NACK
		bootloader_send_nack ();
	}
}

void bootloader_handle_gethelp_cmd (uint8_t *pBuffer)
{
	// Varify the checksum
	printmsg ( "BL_DEBUG_MSG : bootloader_handle_gethelp_cmd \r\n" );

	//Total lenght of the command packet
	uint32_t command_packet_len = bl_rx_buffer[0]+1 ;

	//extract the CRC32 sent by the host
	uint32_t host_crc = *((uint32_t *) (bl_rx_buffer + command_packet_len - 4 ));

	if ( ! bootloader_verify_crc ( &bl_rx_buffer[0], command_packet_len - 4, host_crc) )
	{
		printmsg ( "BL_DEBUG_MSG : checksum success ! !\r\n" );
		// checksum is correct..
		bootloader_send_ack ( pBuffer[0], sizeof ( supported_commands ) );
		printmsg ( "BL_DEBUG_MSG : BL_HELP \r\n" );
		for ( int i=0; i<12 ; i++ )
		printmsg ( "%d %#x \r\n", supported_commands[i], supported_commands[i] );
		bootloader_uart_write_data ( supported_commands, sizeof ( supported_commands ) );
	}
	else
	{
		printmsg ( "BL_DEBUG_MSG : checksum fail ! !\r\n" );
		// checksum is wrong send NACK
		bootloader_send_nack ();
	}
}

void bootloader_handle_getcid_cmd (uint8_t *pBuffer)
{
	uint16_t bl_cid_num = 0;
	// Varify the checksum
	printmsg ( "BL_DEBUG_MSG : bootloader_handle_getcid_cmd \r\n" );

	//Total lenght of the command packet
	uint32_t command_packet_len = bl_rx_buffer[0]+1 ;

	//extract the CRC32 sent by the host
	uint32_t host_crc = *((uint32_t *) (bl_rx_buffer + command_packet_len - 4 ));

	if ( ! bootloader_verify_crc ( &bl_rx_buffer[0], command_packet_len - 4, host_crc) )
	{
		printmsg ( "BL_DEBUG_MSG : checksum success ! !\r\n" );
		// checksum is correct..
		bootloader_send_ack ( pBuffer[0], 2 );
		bl_cid_num = (uint16_t) HAL_GetDEVID ();
		printmsg ( "BL_DEBUG_MSG : BL_HELP %d %#x \r\n", bl_cid_num, bl_cid_num );
		bootloader_uart_write_data ( (uint8_t *)&bl_cid_num, 2 );
	}
	else
	{
		printmsg ( "BL_DEBUG_MSG : checksum fail ! !\r\n" );
		// checksum is wrong send NACK
		bootloader_send_nack ();
	}
}

void bootloader_handle_getrdp_cmd (uint8_t *pBuffer)
{
		uint8_t rdp_level = 0x00;
	// Varify the checksum
	printmsg ( "BL_DEBUG_MSG : bootloader_handle_getcid_cmd \r\n" );

	//Total lenght of the command packet
	uint32_t command_packet_len = bl_rx_buffer[0]+1 ;

	//extract the CRC32 sent by the host
	uint32_t host_crc = *((uint32_t *) (bl_rx_buffer + command_packet_len - 4 ));

	if ( ! bootloader_verify_crc ( &bl_rx_buffer[0], command_packet_len - 4, host_crc) )
	{
		printmsg ( "BL_DEBUG_MSG : checksum success ! !\r\n" );
		// checksum is correct..
		bootloader_send_ack ( pBuffer[0], 1 );
		rdp_level = get_flash_rdp_level ();
		printmsg ( "BL_DEBUG_MSG : RDP_Level %d %#x \r\n", rdp_level, rdp_level );
		bootloader_uart_write_data ( &rdp_level, 1 );
	}
	else
	{
		printmsg ( "BL_DEBUG_MSG : checksum fail ! !\r\n" );
		// checksum is wrong send NACK
		bootloader_send_nack ();
	}
}

void bootloader_handle_go_cmd (uint8_t *pBuffer)
{
	uint32_t go_address = 0;
	uint8_t addr_valid = ADDR_VALID;
	uint8_t addr_invalid = ADDR_INVALID;

	printmsg ( "BL_DEBUG_MSG : bootloader_handle_go_cmd \r\n" );

	//Total lenght of the command packet
	uint32_t command_packet_len = bl_rx_buffer[0]+1 ;

	//extract the CRC32 sent by the host
	uint32_t host_crc = *((uint32_t *) (bl_rx_buffer + command_packet_len - 4 ));

	// Varify the checksum
	if ( ! bootloader_verify_crc ( &bl_rx_buffer[0], command_packet_len - 4, host_crc) )
	{
		// checksum is correct..
		printmsg ( "BL_DEBUG_MSG : checksum success ! !\r\n" );
		bootloader_send_ack ( pBuffer[0], 1 );

		//extract the go address
		go_address = *((uint32_t*)&pBuffer[2]);
		printmsg ( "BL_DEBUG_MSG : Go addr %#x \r\n", go_address );

		if ( verify_address(go_address) == ADDR_VALID )
		{
			//TELL host that the address is valid
			bootloader_uart_write_data ( &addr_valid,1);

			/* Jump to Go_address.
			we dont care what is being done there.
			host must ensure  that the valid code is present over there
			it not the duty of bootloader. so just trust and jump */

			/* Not doing the below line will result in hardfault exception for ARM cortex M */
			//watch : https://www.youtube.com/watch?v=VX_12SjnNhY

			go_address+=1; //make T-bit =1

			void (*lets_jump) (void) = (void *) go_address;
			printmsg ("BL_DEBUG_MSG: jumping to go address! \r\n");
			lets_jump();
		}
		else
			{
				printmsg ("BL_DEBUG_MSG: go addr invalid ! \r\n");
				// tell host that address is invalid
				bootloader_uart_write_data (&addr_invalid,1);
			}
	}
	else
	{
		printmsg ( "BL_DEBUG_MSG : checksum fail ! !\r\n" );
		// checksum is wrong send NACK
		bootloader_send_nack ();
	}
}

void bootloader_handle_flash_erase_cmd (uint8_t *pBuffer)
{
	uint8_t erase_status = 0x00;
    printmsg("BL_DEBUG_MSG:bootloader_handle_flash_erase_cmd\n");

    //Total length of the command packet
	uint32_t command_packet_len = bl_rx_buffer[0]+1 ;

	//extract the CRC32 sent by the Host
	uint32_t host_crc = *((uint32_t * ) (bl_rx_buffer+command_packet_len - 4) ) ;

	if (! bootloader_verify_crc ( &bl_rx_buffer[0],command_packet_len - 4,host_crc))
	{
        printmsg("BL_DEBUG_MSG:checksum success !!\r\n");
        bootloader_send_ack(pBuffer[0],1);
        printmsg("BL_DEBUG_MSG:initial_sector : %d  no_ofsectors: %d\r\n",pBuffer[2],pBuffer[3]);

        HAL_GPIO_WritePin(LD3_GPIO_Port, LD3_Pin,1);
        erase_status = execute_flash_erase(pBuffer[2] , pBuffer[3]);
        HAL_GPIO_WritePin(LD3_GPIO_Port, LD3_Pin,0);

        printmsg("BL_DEBUG_MSG: flash erase status: %#x\r\n",erase_status);

        bootloader_uart_write_data(&erase_status,1);

	}else
	{
        printmsg("BL_DEBUG_MSG:checksum fail !!\r\n");
        bootloader_send_nack();
	}
}

/*Helper function to handle BL_MEM_WRITE command */
void bootloader_handle_mem_write_cmd(uint8_t *pBuffer)
{
//	uint8_t addr_valid = ADDR_VALID;
	uint8_t write_status = 0x00, chksum =0;
	uint8_t len=0;
	len = pBuffer[0];
	uint8_t payload_len = pBuffer[6];

	uint32_t mem_address = *((uint32_t *) ( &pBuffer[2]) );

	chksum = pBuffer[len];

    printmsg("BL_DEBUG_MSG:bootloader_handle_mem_write_cmd\r\n");

    //Total length of the command packet
	uint32_t command_packet_len = bl_rx_buffer[0]+1 ;

	//extract the CRC32 sent by the Host
	uint32_t host_crc = *((uint32_t * ) (bl_rx_buffer+command_packet_len - 4) ) ;

	if (! bootloader_verify_crc(&bl_rx_buffer[0],command_packet_len-4,host_crc))
	{
        printmsg("BL_DEBUG_MSG:checksum success !!\r\n");

        bootloader_send_ack(pBuffer[0],1);

        printmsg("BL_DEBUG_MSG: mem write address : %#x\r\n",mem_address);

		if( verify_address(mem_address) == ADDR_VALID )
		{

            printmsg("BL_DEBUG_MSG: valid mem write address\r\n");

            //glow the led to indicate bootloader is currently writing to memory
            HAL_GPIO_WritePin(LD3_GPIO_Port, LD3_Pin, GPIO_PIN_SET);

            //execute mem write
            write_status = execute_mem_write(&pBuffer[7],mem_address, payload_len);

            //turn off the led to indicate memory write is over
            HAL_GPIO_WritePin(LD3_GPIO_Port, LD3_Pin, GPIO_PIN_RESET);

            //inform host about the status
            bootloader_uart_write_data(&write_status,1);

		}
		else
		{
            printmsg("BL_DEBUG_MSG: invalid mem write address\r\n");
            write_status = ADDR_INVALID;
            //inform host that address is invalid
            bootloader_uart_write_data(&write_status,1);
		}

	}else
	{
        printmsg("BL_DEBUG_MSG:checksum fail !!\r\n");
        bootloader_send_nack();
	}

}

/*Helper function to handle BL_EN_RW_PROTECT  command */
void bootloader_handle_en_rw_protect(uint8_t *pBuffer)
{
    uint8_t status = 0x00;
    printmsg("BL_DEBUG_MSG:bootloader_handle_endis_rw_protect\r\n");

    //Total length of the command packet
	uint32_t command_packet_len = bl_rx_buffer[0]+1 ;

	//extract the CRC32 sent by the Host
	uint32_t host_crc = *((uint32_t * ) (bl_rx_buffer+command_packet_len - 4) ) ;

	if (! bootloader_verify_crc(&bl_rx_buffer[0],command_packet_len-4,host_crc))
	{
        printmsg("BL_DEBUG_MSG:checksum success !!\r\n");
        bootloader_send_ack(pBuffer[0],1);

        status = configure_flash_sector_rw_protection(pBuffer[2] , pBuffer[3],0);

        printmsg("BL_DEBUG_MSG: flash erase status: %#x\r\n",status);

        bootloader_uart_write_data(&status,1);

	}else
	{
        printmsg("BL_DEBUG_MSG:checksum fail !!\r\n");
        bootloader_send_nack();
	}

}

/*Helper function to handle BL_DIS_RW_PROTECT  command */
void bootloader_handle_dis_rw_protect(uint8_t *pBuffer)
{
    uint8_t status = 0x00;
    printmsg("BL_DEBUG_MSG:bootloader_handle_dis_rw_protect\r\n");

    //Total length of the command packet
	uint32_t command_packet_len = bl_rx_buffer[0]+1 ;

	//extract the CRC32 sent by the Host
	uint32_t host_crc = *((uint32_t * ) (bl_rx_buffer+command_packet_len - 4) ) ;

	if (! bootloader_verify_crc(&bl_rx_buffer[0],command_packet_len-4,host_crc))
	{
        printmsg("BL_DEBUG_MSG:checksum success !!\r\n");
        bootloader_send_ack(pBuffer[0],1);

        status = configure_flash_sector_rw_protection(0,0,1);

        printmsg("BL_DEBUG_MSG: flash erase status: %#x\r\n",status);

        bootloader_uart_write_data(&status,1);

	}else
	{
        printmsg("BL_DEBUG_MSG:checksum fail !!\r\n");
        bootloader_send_nack();
	}

}

/*Helper function to handle BL_MEM_READ command */
void bootloader_handle_mem_read (uint8_t *pBuffer)
{

}

/*Helper function to handle _BL_READ_SECTOR_P_STATUS command */
void bootloader_handle_read_sector_protection_status(uint8_t *pBuffer)
{
	 uint16_t status;
	printmsg("BL_DEBUG_MSG:bootloader_handle_read_sector_protection_status\r\n");

    //Total length of the command packet
	uint32_t command_packet_len = bl_rx_buffer[0]+1 ;

	//extract the CRC32 sent by the Host
	uint32_t host_crc = *((uint32_t * ) (bl_rx_buffer+command_packet_len - 4) ) ;

	if (! bootloader_verify_crc(&bl_rx_buffer[0],command_packet_len-4,host_crc))
	{
        printmsg("BL_DEBUG_MSG:checksum success !!\r\n");
        bootloader_send_ack(pBuffer[0],2);
        status=read_OB_rw_protection_status();
        printmsg("BL_DEBUG_MSG: nWRP status: %#x\r\n",status);
        bootloader_uart_write_data((uint8_t*)&status,2);

	}else
	{
        printmsg("BL_DEBUG_MSG:checksum fail !!\r\n");
        bootloader_send_nack();
	}

}

void bootloader_handle_read_otp (uint8_t *pBuffer)
{
}

/* this function sends ACK if CRC matches along with "len to follow " */
void bootloader_send_ack (uint8_t command_code, uint8_t follow_len)
{
	// we send 2 bytes.. first byte is ack and the second byte is len value
	uint8_t ack_buf[2];
	ack_buf[0] = BL_ACK;
	ack_buf[1] = follow_len;
	HAL_UART_Transmit ( D_UART, ack_buf, 2, HAL_MAX_DELAY );
}

void bootloader_send_nack ( void )
{
	uint8_t nack = BL_NACK;
	HAL_UART_Transmit ( D_UART, &nack, 1, HAL_MAX_DELAY );
}

/* Varifies the CRC of the given buffer in pDATA		*/
uint8_t bootloader_verify_crc (uint8_t *pData, uint32_t len, uint32_t crc_host)
{
    uint32_t uwCRCValue=0xff;

    for (uint32_t i=0 ; i < len ; i++)
	{
        uint32_t i_data = pData[i];
        uwCRCValue = HAL_CRC_Accumulate(&hcrc, &i_data, 1);
	}

	 /* Reset CRC Calculation Unit */
  __HAL_CRC_DR_RESET(&hcrc);

	if( uwCRCValue == crc_host)
	{
		return VERIFY_CRC_SUCCESS;
	}

	return VERIFY_CRC_FAIL;
}

void bootloader_uart_write_data ( uint8_t *pBuffer, uint32_t len )
{
	// can be replace by specific MCU driver
	HAL_UART_Transmit(C_UART,pBuffer,len,HAL_MAX_DELAY);
//	HAL_UART_Transmit ( C_UART, pBuffer, len, HAL_MAX_DELAY );
	//HAL_UART_Transmit ( D_UART, pBuffer, len, HAL_MAX_DELAY );
	printmsg ( "BL_DEBUG_MSG : in Uart_write_data ! !\r\n" );
}

uint8_t get_bootloader_version ( void )
{
	return (uint8_t) BL_VERSION;

}

//Read the chip identifier or device Identifier
uint16_t get_mcu_chip_id(void)
{
/*
	The STM32F446xx MCUs integrate an MCU ID code. This ID identifies the ST MCU partnumber
	and the die revision. It is part of the DBG_MCU component and is mapped on the
	external PPB bus (see Section 33.16 on page 1304). This code is accessible using the
	JTAG debug pCat.2ort (4 to 5 pins) or the SW debug port (two pins) or by the user software.
	It is even accessible while the MCU is under system reset. */
	uint16_t cid;
	cid = (uint16_t)(DBGMCU->IDCODE) & 0x0FFF;
	return  cid;

}

uint8_t get_flash_rdp_level ( void )
{
	uint8_t rdp_status = 0;
	#if 0
		FLASH_OBProgramInitTypeDef ob_handle;
		HAL_FLASHEx_OBGetConfig (&ob_handle);
		rdp_status = (uint8_t) ob_handle.RDPLevel;
	#else

		volatile uint32_t *pOB_addr = (uint32_t *) 0x1FFFC000;
		rdp_status = (uint8_t)(*pOB_addr >> 8);
	#endif
		return rdp_status;
}

// verify the address sent by the host.
uint8_t verify_address (uint32_t go_address)
{
	// valid address to which we can jump?
	// system memory ? yes.
	// sram1 memory ? yes.
	// sram2 memory ? yes.
	// backup sram memory ? yes.
	// external memory ? yes.
	// peripheral memory ? its possible , but dont allow. so no.

	// need to optimize
	if ( go_address >= SRAM1_BASE && go_address <= SRAM1_END )
		return ADDR_VALID;
	else if ( go_address >= SRAM2_BASE && go_address <= SRAM2_END )
		return ADDR_VALID;
	else if ( go_address >= FLASH_BASE && go_address <= FLASH_END )
		return ADDR_VALID;
	else if ( go_address >= BKPSRAM_BASE && go_address <= BKPSRAM_END )
		return ADDR_VALID;
	else
		return ADDR_INVALID;
}

 uint8_t execute_flash_erase(uint8_t sector_number , uint8_t number_of_sector)
{
    //we have totally 12 sectors in STM32F429 mcu .. sector[0 to 11]
	//number_of_sector has to be in the range of 0 to 7
	// if sector_number = 0xff , that means mass erase !
	//Code needs to modified if your MCU supports more flash sectors
	FLASH_EraseInitTypeDef flashErase_handle;
	uint32_t sectorError;
	HAL_StatusTypeDef status;

	if( number_of_sector > 12 )
		return INVALID_SECTOR;

	if( (sector_number == 0xff ) || (sector_number <= 11) )
	{
		if(sector_number == (uint8_t) 0xff)
		{
			flashErase_handle.TypeErase = FLASH_TYPEERASE_MASSERASE;
		}
		else
		{
		    /*Here we are just calculating how many sectors needs to erased */
			uint8_t remanining_sector = 12 - sector_number;
            if( number_of_sector > remanining_sector)
            {
            	number_of_sector = remanining_sector;
            }
			flashErase_handle.TypeErase = FLASH_TYPEERASE_SECTORS;
			flashErase_handle.Sector = sector_number; // this is the initial sector
			flashErase_handle.NbSectors = number_of_sector;
		}
		flashErase_handle.Banks = FLASH_BANK_1;

		/*Get access to touch the flash registers */
		HAL_FLASH_Unlock();
		flashErase_handle.VoltageRange = FLASH_VOLTAGE_RANGE_3;  // our mcu will work on this voltage range
		status = (uint8_t) HAL_FLASHEx_Erase(&flashErase_handle, &sectorError);
		HAL_FLASH_Lock();

		return status;
	}
}

/*This function writes the contents of pBuffer to  "mem_address" byte by byte */
//Note1 : Currently this function supports writing to Flash only .
//Note2 : This functions does not check whether "mem_address" is a valid address of the flash range.
uint8_t execute_mem_write(uint8_t *pBuffer, uint32_t mem_address, uint32_t len)
{
    uint8_t status=HAL_OK;

    //We have to unlock flash module to get control of registers
    HAL_FLASH_Unlock();

    for(uint32_t i = 0 ; i <len ; i++)
    {
        //Here we program the flash byte by byte
        status = HAL_FLASH_Program(FLASH_TYPEPROGRAM_BYTE,mem_address+i,pBuffer[i] );
    }

    HAL_FLASH_Lock();

    return status;
}

/*
Modifying user option bytes
To modify the user option value, follow the sequence below:
1. Check that no Flash memory operation is ongoing by checking the BSY bit in the
FLASH_SR register
2. Write the desired option value in the FLASH_OPTCR register.
3. Set the option start bit (OPTSTRT) in the FLASH_OPTCR register
4. Wait for the BSY bit to be cleared.
*/
uint8_t configure_flash_sector_rw_protection(uint8_t sector_details, uint8_t protection_mode, uint8_t disable)
{
    //First configure the protection mode
    //protection_mode =1 , means write protect of the user flash sectors
    //protection_mode =2, means read/write protect of the user flash sectors
    //According to RM of stm32f446xx TABLE 9, We have to modify the address 0x1FFF C008 bit 15(SPRMOD)

	 //Flash option control register (OPTCR)
    volatile uint32_t *pOPTCR = (uint32_t*) 0x40023C14;

	  if(disable)
		{

			//disable all r/w protection on sectors

			//Option byte configuration unlock
			HAL_FLASH_OB_Unlock();

			//wait till no active operation on flash
			while(__HAL_FLASH_GET_FLAG(FLASH_FLAG_BSY) != RESET);

			//clear the 31st bit (default state)
			//please refer : Flash option control register (FLASH_OPTCR) in RM
			*pOPTCR &= ~(1 << 31);

			//clear the protection : make all bits belonging to sectors as 1
			*pOPTCR |= (0xFF << 16);

			//Set the option start bit (OPTSTRT) in the FLASH_OPTCR register
			*pOPTCR |= ( 1 << 1);

			//wait till no active operation on flash
			while(__HAL_FLASH_GET_FLAG(FLASH_FLAG_BSY) != RESET);

			HAL_FLASH_OB_Lock();

			return 0;

		}

	   if(protection_mode == (uint8_t) 1)
    {
           //we are putting write protection on the sectors encoded in sector_details argument

			//Option byte configuration unlock
			HAL_FLASH_OB_Unlock();

			//wait till no active operation on flash
			while(__HAL_FLASH_GET_FLAG(FLASH_FLAG_BSY) != RESET);

			//here we are setting just write protection for the sectors
			//clear the 31st bit
			//please refer : Flash option control register (FLASH_OPTCR) in RM
			*pOPTCR &= ~(1 << 31);

			//put write protection on sectors
			*pOPTCR &= ~ (sector_details << 16);

			//Set the option start bit (OPTSTRT) in the FLASH_OPTCR register
			*pOPTCR |= ( 1 << 1);

			//wait till no active operation on flash
			while(__HAL_FLASH_GET_FLAG(FLASH_FLAG_BSY) != RESET);

			HAL_FLASH_OB_Lock();
		}

		else if (protection_mode == (uint8_t) 2)
    {
	  	//Option byte configuration unlock
			HAL_FLASH_OB_Unlock();

			//wait till no active operation on flash
			while(__HAL_FLASH_GET_FLAG(FLASH_FLAG_BSY) != RESET);

			//here wer are setting read and write protection for the sectors
			//set the 31st bit
			//please refer : Flash option control register (FLASH_OPTCR) in RM
			*pOPTCR |= (1 << 31);

			//put read and write protection on sectors
      *pOPTCR &= ~(0xff << 16);
			*pOPTCR |= (sector_details << 16);

			//Set the option start bit (OPTSTRT) in the FLASH_OPTCR register
			*pOPTCR |= ( 1 << 1);

			//wait till no active operation on flash
			while(__HAL_FLASH_GET_FLAG(FLASH_FLAG_BSY) != RESET);

			HAL_FLASH_OB_Lock();
    }

		return 0;
}

uint16_t read_OB_rw_protection_status(void)
{
    //This structure is given by ST Flash driver to hold the OB(Option Byte) contents .
	FLASH_OBProgramInitTypeDef OBInit;

	//First unlock the OB(Option Byte) memory access
	HAL_FLASH_OB_Unlock();
	//get the OB configuration details
	HAL_FLASHEx_OBGetConfig(&OBInit);
	//Lock back .
	HAL_FLASH_Lock();

	//We are just interested in r/w protection status of the sectors.
	return (uint16_t)OBInit.WRPSector;

}
